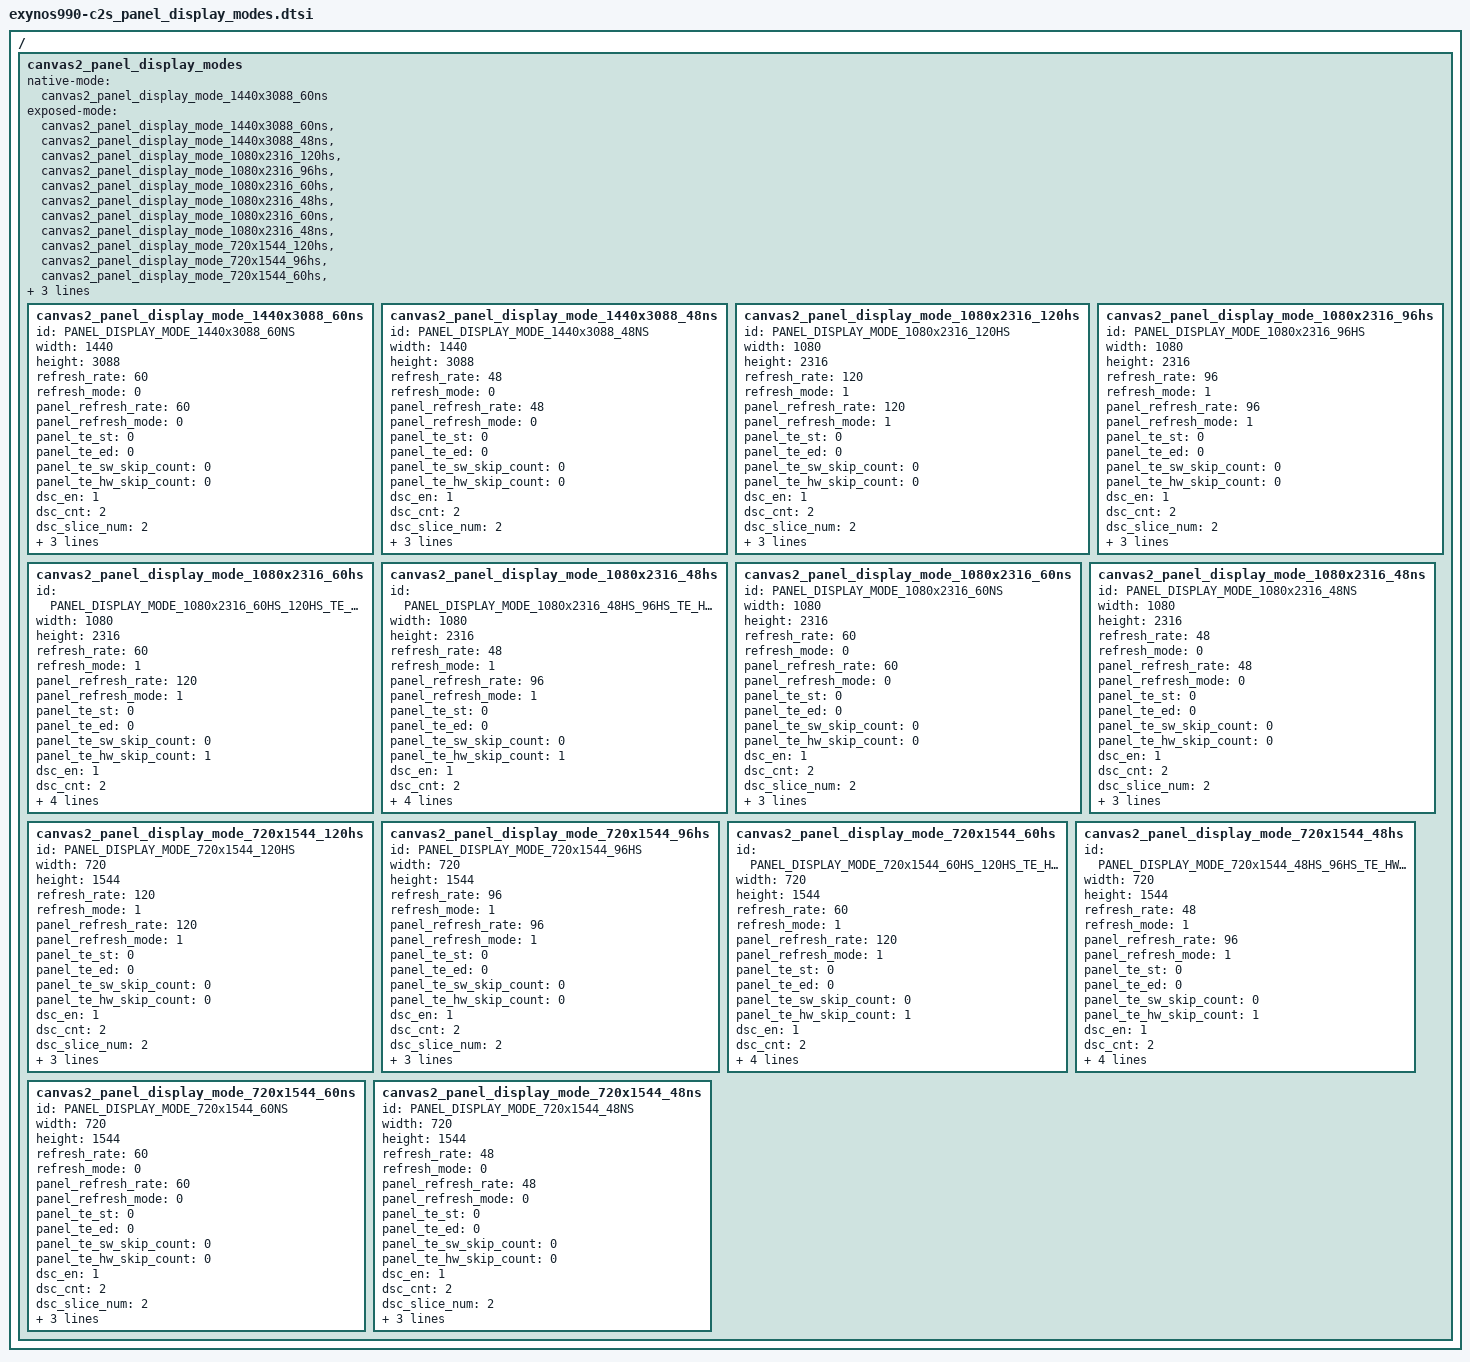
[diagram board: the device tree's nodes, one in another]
/*
 * SAMSUNG LCD Panel Device Tree Source
 *
 * Copyright (c) 2020 Samsung Electronics Co., Ltd.
 *		http://www.samsung.com
 *
 * This program is free software; you can redistribute it and/or modify
 * it under the terms of the GNU General Public License version 2 as
 * published by the Free Software Foundation.
 */

#include <dt-bindings/display/panel-display.h>

/ {
	fragment@panel_display_modes {
		target-path = "/";
		__overlay__ {
			canvas2_panel_display_modes:
			canvas2_panel_display_modes {
				native-mode = <&canvas2_panel_display_mode_1440x3088_60ns>;
				exposed-mode = <
					&canvas2_panel_display_mode_1440x3088_60ns
					&canvas2_panel_display_mode_1440x3088_48ns
					&canvas2_panel_display_mode_1080x2316_120hs
					&canvas2_panel_display_mode_1080x2316_96hs
					&canvas2_panel_display_mode_1080x2316_60hs
					&canvas2_panel_display_mode_1080x2316_48hs
					&canvas2_panel_display_mode_1080x2316_60ns
					&canvas2_panel_display_mode_1080x2316_48ns
					&canvas2_panel_display_mode_720x1544_120hs
					&canvas2_panel_display_mode_720x1544_96hs
					&canvas2_panel_display_mode_720x1544_60hs
					&canvas2_panel_display_mode_720x1544_48hs
					&canvas2_panel_display_mode_720x1544_60ns
					&canvas2_panel_display_mode_720x1544_48ns
				>;
				/* wqhd */
				canvas2_panel_display_mode_1440x3088_60ns:
				canvas2_panel_display_mode_1440x3088_60ns {
					id = PANEL_DISPLAY_MODE_1440x3088_60NS;
					width = <1440>;
					height = <3088>;
					/* timing parameters */
					refresh_rate = <60>;			/* logical refresh rate */
					refresh_mode = <0>;				/* 0:NS, 1:HS */
					panel_refresh_rate = <60>;		/* panel internal refresh rate */
					panel_refresh_mode = <0>;		/* 0:NS, 1:HS */
					panel_te_st = <0>;				/* te rising */
					panel_te_ed = <0>;				/* te falling */
					panel_te_sw_skip_count = <0>;	/* s/w te modulation */
					panel_te_hw_skip_count = <0>;	/* h/w te modulation */
					/* dsc parameters */
					dsc_en = <1>;			/* 0:Disable, 1:Enable */
					dsc_cnt = <2>;			/* used DSC count */
					dsc_slice_num = <2>;	/* count of dsc slice */
					dsc_slice_w = <720>;	/* width of dsc slice */
					dsc_slice_h = <193>;	/* height of dsc slice */
					/* dsi parameters */
					cmd_lp_ref = <5324>;
				};

				canvas2_panel_display_mode_1440x3088_48ns:
				canvas2_panel_display_mode_1440x3088_48ns {
					id = PANEL_DISPLAY_MODE_1440x3088_48NS;
					width = <1440>;
					height = <3088>;
					/* timing parameters */
					refresh_rate = <48>;			/* logical refresh rate */
					refresh_mode = <0>;				/* 0:NS, 1:HS */
					panel_refresh_rate = <48>;		/* panel internal refresh rate */
					panel_refresh_mode = <0>;		/* 0:NS, 1:HS */
					panel_te_st = <0>;				/* te rising */
					panel_te_ed = <0>;				/* te falling */
					panel_te_sw_skip_count = <0>;	/* s/w te modulation */
					panel_te_hw_skip_count = <0>;	/* h/w te modulation */
					/* dsc parameters */
					dsc_en = <1>;			/* 0:Disable, 1:Enable */
					dsc_cnt = <2>;			/* used DSC count */
					dsc_slice_num = <2>;	/* count of dsc slice */
					dsc_slice_w = <720>;	/* width of dsc slice */
					dsc_slice_h = <193>;	/* height of dsc slice */
					/* dsi parameters */
					cmd_lp_ref = <5324>;
				};

				/* fhd */
				canvas2_panel_display_mode_1080x2316_120hs:
				canvas2_panel_display_mode_1080x2316_120hs {
					id = PANEL_DISPLAY_MODE_1080x2316_120HS;
					width = <1080>;
					height = <2316>;
					/* timing parameters */
					refresh_rate = <120>;			/* logical refresh rate */
					refresh_mode = <1>;				/* 0:NS, 1:HS */
					panel_refresh_rate = <120>;		/* panel internal refresh rate */
					panel_refresh_mode = <1>;		/* 0:NS, 1:HS */
					panel_te_st = <0>;				/* te rising */
					panel_te_ed = <0>;				/* te falling */
					panel_te_sw_skip_count = <0>;	/* s/w te modulation */
					panel_te_hw_skip_count = <0>;	/* h/w te modulation */
					/* dsc parameters */
					dsc_en = <1>;			/* 0:Disable, 1:Enable */
					dsc_cnt = <2>;			/* used DSC count */
					dsc_slice_num = <2>;	/* count of dsc slice */
					dsc_slice_w = <540>;	/* width of dsc slice */
					dsc_slice_h = <193>;	/* height of dsc slice */
					/* dsi parameters */
					cmd_lp_ref = <7766>;
				};

				canvas2_panel_display_mode_1080x2316_96hs:
				canvas2_panel_display_mode_1080x2316_96hs {
					id = PANEL_DISPLAY_MODE_1080x2316_96HS;
					width = <1080>;
					height = <2316>;
					/* timing parameters */
					refresh_rate = <96>;			/* logical refresh rate */
					refresh_mode = <1>;				/* 0:NS, 1:HS */
					panel_refresh_rate = <96>;		/* panel internal refresh rate */
					panel_refresh_mode = <1>;		/* 0:NS, 1:HS */
					panel_te_st = <0>;				/* te rising */
					panel_te_ed = <0>;				/* te falling */
					panel_te_sw_skip_count = <0>;	/* s/w te modulation */
					panel_te_hw_skip_count = <0>;	/* h/w te modulation */
					/* dsc parameters */
					dsc_en = <1>;			/* 0:Disable, 1:Enable */
					dsc_cnt = <2>;			/* used DSC count */
					dsc_slice_num = <2>;	/* count of dsc slice */
					dsc_slice_w = <540>;	/* width of dsc slice */
					dsc_slice_h = <193>;	/* height of dsc slice */
					/* dsi parameters */
					cmd_lp_ref = <7766>;
				};

				canvas2_panel_display_mode_1080x2316_60hs:
				canvas2_panel_display_mode_1080x2316_60hs {
					id = PANEL_DISPLAY_MODE_1080x2316_60HS_120HS_TE_HW_SKIP_1;
					width = <1080>;
					height = <2316>;
					/* timing parameters */
					refresh_rate = <60>;			/* logical refresh rate */
					refresh_mode = <1>;				/* 0:NS, 1:HS */
					panel_refresh_rate = <120>;		/* panel internal refresh rate */
					panel_refresh_mode = <1>;		/* 0:NS, 1:HS */
					panel_te_st = <0>;				/* te rising */
					panel_te_ed = <0>;				/* te falling */
					panel_te_sw_skip_count = <0>;	/* s/w te modulation */
					panel_te_hw_skip_count = <1>;	/* h/w te modulation */
					/* dsc parameters */
					dsc_en = <1>;			/* 0:Disable, 1:Enable */
					dsc_cnt = <2>;			/* used DSC count */
					dsc_slice_num = <2>;	/* count of dsc slice */
					dsc_slice_w = <540>;	/* width of dsc slice */
					dsc_slice_h = <193>;	/* height of dsc slice */
					/* dsi parameters */
					cmd_lp_ref = <7766>;
				};

				canvas2_panel_display_mode_1080x2316_48hs:
				canvas2_panel_display_mode_1080x2316_48hs {
					id = PANEL_DISPLAY_MODE_1080x2316_48HS_96HS_TE_HW_SKIP_1;
					width = <1080>;
					height = <2316>;
					/* timing parameters */
					refresh_rate = <48>;			/* logical refresh rate */
					refresh_mode = <1>;				/* 0:NS, 1:HS */
					panel_refresh_rate = <96>;		/* panel internal refresh rate */
					panel_refresh_mode = <1>;		/* 0:NS, 1:HS */
					panel_te_st = <0>;				/* te rising */
					panel_te_ed = <0>;				/* te falling */
					panel_te_sw_skip_count = <0>;	/* s/w te modulation */
					panel_te_hw_skip_count = <1>;	/* h/w te modulation */
					/* dsc parameters */
					dsc_en = <1>;			/* 0:Disable, 1:Enable */
					dsc_cnt = <2>;			/* used DSC count */
					dsc_slice_num = <2>;	/* count of dsc slice */
					dsc_slice_w = <540>;	/* width of dsc slice */
					dsc_slice_h = <193>;	/* height of dsc slice */
					/* dsi parameters */
					cmd_lp_ref = <7766>;
				};

				canvas2_panel_display_mode_1080x2316_60ns:
				canvas2_panel_display_mode_1080x2316_60ns {
					id = PANEL_DISPLAY_MODE_1080x2316_60NS;
					width = <1080>;
					height = <2316>;
					/* timing parameters */
					refresh_rate = <60>;			/* logical refresh rate */
					refresh_mode = <0>;				/* 0:NS, 1:HS */
					panel_refresh_rate = <60>;		/* panel internal refresh rate */
					panel_refresh_mode = <0>;		/* 0:NS, 1:HS */
					panel_te_st = <0>;				/* te rising */
					panel_te_ed = <0>;				/* te falling */
					panel_te_sw_skip_count = <0>;	/* s/w te modulation */
					panel_te_hw_skip_count = <0>;	/* h/w te modulation */
					/* dsc parameters */
					dsc_en = <1>;			/* 0:Disable, 1:Enable */
					dsc_cnt = <2>;			/* used DSC count */
					dsc_slice_num = <2>;	/* count of dsc slice */
					dsc_slice_w = <540>;	/* width of dsc slice */
					dsc_slice_h = <193>;	/* height of dsc slice */
					/* dsi parameters */
					cmd_lp_ref = <7766>;
				};

				canvas2_panel_display_mode_1080x2316_48ns:
				canvas2_panel_display_mode_1080x2316_48ns {
					id = PANEL_DISPLAY_MODE_1080x2316_48NS;
					width = <1080>;
					height = <2316>;
					/* timing parameters */
					refresh_rate = <48>;			/* logical refresh rate */
					refresh_mode = <0>;				/* 0:NS, 1:HS */
					panel_refresh_rate = <48>;		/* panel internal refresh rate */
					panel_refresh_mode = <0>;		/* 0:NS, 1:HS */
					panel_te_st = <0>;				/* te rising */
					panel_te_ed = <0>;				/* te falling */
					panel_te_sw_skip_count = <0>;	/* s/w te modulation */
					panel_te_hw_skip_count = <0>;	/* h/w te modulation */
					/* dsc parameters */
					dsc_en = <1>;			/* 0:Disable, 1:Enable */
					dsc_cnt = <2>;			/* used DSC count */
					dsc_slice_num = <2>;	/* count of dsc slice */
					dsc_slice_w = <540>;	/* width of dsc slice */
					dsc_slice_h = <193>;	/* height of dsc slice */
					/* dsi parameters */
					cmd_lp_ref = <7766>;
				};

				/* hd */
				canvas2_panel_display_mode_720x1544_120hs:
				canvas2_panel_display_mode_720x1544_120hs {
					id = PANEL_DISPLAY_MODE_720x1544_120HS;
					width = <720>;
					height = <1544>;
					/* timing parameters */
					refresh_rate = <120>;			/* logical refresh rate */
					refresh_mode = <1>;				/* 0:NS, 1:HS */
					panel_refresh_rate = <120>;		/* panel internal refresh rate */
					panel_refresh_mode = <1>;		/* 0:NS, 1:HS */
					panel_te_st = <0>;				/* te rising */
					panel_te_ed = <0>;				/* te falling */
					panel_te_sw_skip_count = <0>;	/* s/w te modulation */
					panel_te_hw_skip_count = <0>;	/* h/w te modulation */
					/* dsc parameters */
					dsc_en = <1>;			/* 0:Disable, 1:Enable */
					dsc_cnt = <2>;			/* used DSC count */
					dsc_slice_num = <2>;	/* count of dsc slice */
					dsc_slice_w = <360>;	/* width of dsc slice */
					dsc_slice_h = <193>;	/* height of dsc slice */
					/* dsi parameters */
					cmd_lp_ref = <9509>;
				};

				canvas2_panel_display_mode_720x1544_96hs:
				canvas2_panel_display_mode_720x1544_96hs {
					id = PANEL_DISPLAY_MODE_720x1544_96HS;
					width = <720>;
					height = <1544>;
					/* timing parameters */
					refresh_rate = <96>;			/* logical refresh rate */
					refresh_mode = <1>;				/* 0:NS, 1:HS */
					panel_refresh_rate = <96>;		/* panel internal refresh rate */
					panel_refresh_mode = <1>;		/* 0:NS, 1:HS */
					panel_te_st = <0>;				/* te rising */
					panel_te_ed = <0>;				/* te falling */
					panel_te_sw_skip_count = <0>;	/* s/w te modulation */
					panel_te_hw_skip_count = <0>;	/* h/w te modulation */
					/* dsc parameters */
					dsc_en = <1>;			/* 0:Disable, 1:Enable */
					dsc_cnt = <2>;			/* used DSC count */
					dsc_slice_num = <2>;	/* count of dsc slice */
					dsc_slice_w = <360>;	/* width of dsc slice */
					dsc_slice_h = <193>;	/* height of dsc slice */
					/* dsi parameters */
					cmd_lp_ref = <9509>;
				};

				canvas2_panel_display_mode_720x1544_60hs:
				canvas2_panel_display_mode_720x1544_60hs {
					id = PANEL_DISPLAY_MODE_720x1544_60HS_120HS_TE_HW_SKIP_1;
					width = <720>;
					height = <1544>;
					/* timing parameters */
					refresh_rate = <60>;			/* logical refresh rate */
					refresh_mode = <1>;				/* 0:NS, 1:HS */
					panel_refresh_rate = <120>;		/* panel internal refresh rate */
					panel_refresh_mode = <1>;		/* 0:NS, 1:HS */
					panel_te_st = <0>;				/* te rising */
					panel_te_ed = <0>;				/* te falling */
					panel_te_sw_skip_count = <0>;	/* s/w te modulation */
					panel_te_hw_skip_count = <1>;	/* h/w te modulation */
					/* dsc parameters */
					dsc_en = <1>;			/* 0:Disable, 1:Enable */
					dsc_cnt = <2>;			/* used DSC count */
					dsc_slice_num = <2>;	/* count of dsc slice */
					dsc_slice_w = <360>;	/* width of dsc slice */
					dsc_slice_h = <193>;	/* height of dsc slice */
					/* dsi parameters */
					cmd_lp_ref = <9509>;
				};

				canvas2_panel_display_mode_720x1544_48hs:
				canvas2_panel_display_mode_720x1544_48hs {
					id = PANEL_DISPLAY_MODE_720x1544_48HS_96HS_TE_HW_SKIP_1;
					width = <720>;
					height = <1544>;
					/* timing parameters */
					refresh_rate = <48>;			/* logical refresh rate */
					refresh_mode = <1>;				/* 0:NS, 1:HS */
					panel_refresh_rate = <96>;		/* panel internal refresh rate */
					panel_refresh_mode = <1>;		/* 0:NS, 1:HS */
					panel_te_st = <0>;				/* te rising */
					panel_te_ed = <0>;				/* te falling */
					panel_te_sw_skip_count = <0>;	/* s/w te modulation */
					panel_te_hw_skip_count = <1>;	/* h/w te modulation */
					/* dsc parameters */
					dsc_en = <1>;			/* 0:Disable, 1:Enable */
					dsc_cnt = <2>;			/* used DSC count */
					dsc_slice_num = <2>;	/* count of dsc slice */
					dsc_slice_w = <360>;	/* width of dsc slice */
					dsc_slice_h = <193>;	/* height of dsc slice */
					/* dsi parameters */
					cmd_lp_ref = <9509>;
				};

				canvas2_panel_display_mode_720x1544_60ns:
				canvas2_panel_display_mode_720x1544_60ns {
					id = PANEL_DISPLAY_MODE_720x1544_60NS;
					width = <720>;
					height = <1544>;
					/* timing parameters */
					refresh_rate = <60>;			/* logical refresh rate */
					refresh_mode = <0>;				/* 0:NS, 1:HS */
					panel_refresh_rate = <60>;		/* panel internal refresh rate */
					panel_refresh_mode = <0>;		/* 0:NS, 1:HS */
					panel_te_st = <0>;				/* te rising */
					panel_te_ed = <0>;				/* te falling */
					panel_te_sw_skip_count = <0>;	/* s/w te modulation */
					panel_te_hw_skip_count = <0>;	/* h/w te modulation */
					/* dsc parameters */
					dsc_en = <1>;			/* 0:Disable, 1:Enable */
					dsc_cnt = <2>;			/* used DSC count */
					dsc_slice_num = <2>;	/* count of dsc slice */
					dsc_slice_w = <360>;	/* width of dsc slice */
					dsc_slice_h = <193>;	/* height of dsc slice */
					/* dsi parameters */
					cmd_lp_ref = <9509>;
				};

				canvas2_panel_display_mode_720x1544_48ns:
				canvas2_panel_display_mode_720x1544_48ns {
					id = PANEL_DISPLAY_MODE_720x1544_48NS;
					width = <720>;
					height = <1544>;
					/* timing parameters */
					refresh_rate = <48>;			/* logical refresh rate */
					refresh_mode = <0>;				/* 0:NS, 1:HS */
					panel_refresh_rate = <48>;		/* panel internal refresh rate */
					panel_refresh_mode = <0>;		/* 0:NS, 1:HS */
					panel_te_st = <0>;				/* te rising */
					panel_te_ed = <0>;				/* te falling */
					panel_te_sw_skip_count = <0>;	/* s/w te modulation */
					panel_te_hw_skip_count = <0>;	/* h/w te modulation */
					/* dsc parameters */
					dsc_en = <1>;			/* 0:Disable, 1:Enable */
					dsc_cnt = <2>;			/* used DSC count */
					dsc_slice_num = <2>;	/* count of dsc slice */
					dsc_slice_w = <360>;	/* width of dsc slice */
					dsc_slice_h = <193>;	/* height of dsc slice */
					/* dsi parameters */
					cmd_lp_ref = <9509>;
				};
			};
		};
	};
};
